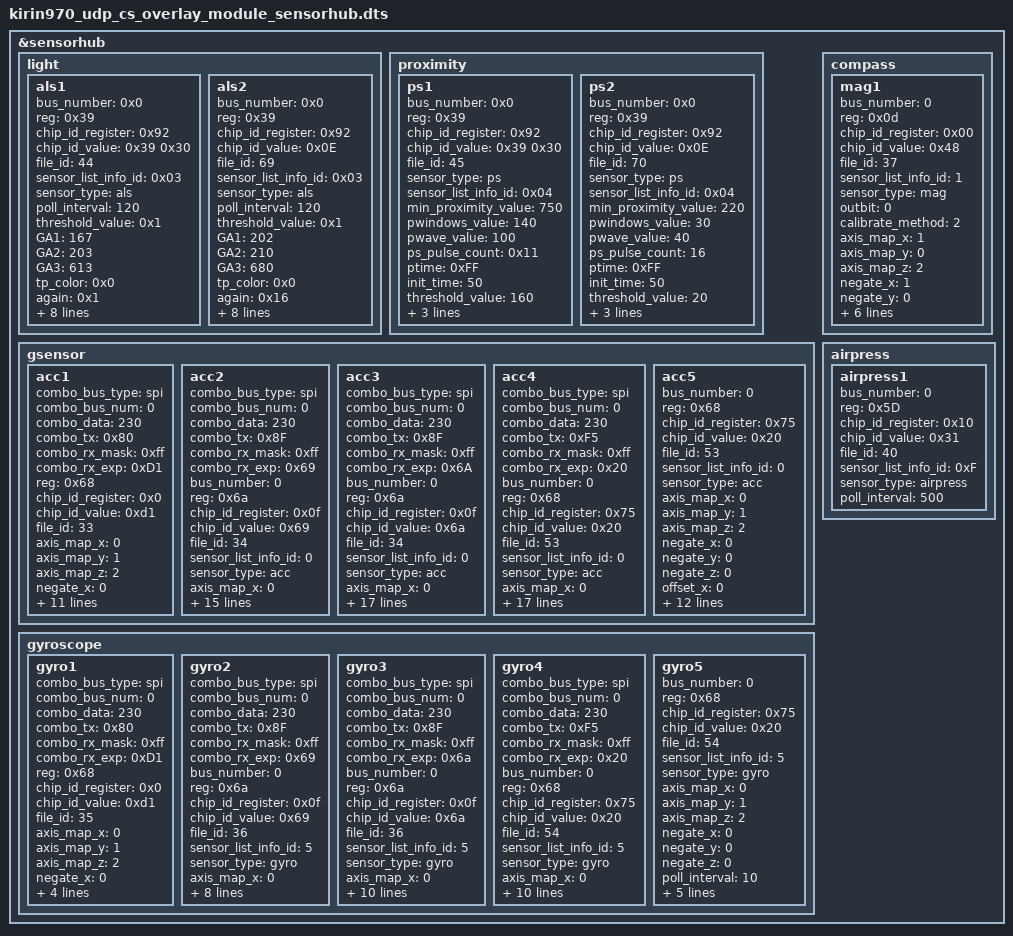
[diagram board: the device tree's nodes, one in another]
&sensorhub {
	#address-cells=<1>;
	#size-cells=<0>;
	light {
		als1 {
			bus_number = <0x0>;
			reg=<0x39>;
			chip_id_register = <0x92>;
			chip_id_value = <0x39 0x30>;
			file_id = <44>;
			sensor_list_info_id = <0x03>;
			sensor_type = "als";
			poll_interval = <120>;
			threshold_value = <0x1>;
			GA1 = <167>;
			GA2 = <203>;
			GA3 = <613>;
			tp_color = <0x0>;
			again = <0x1>;
			atime = <0xdb>;
			init_time = <0x96>;
			status = "ok";
			als_phone_type = <11>;
			als_phone_version = <11>;
			als_extend_data = <214 41 0x0 0x0 0x0 0x0 0x0 0x0 0x0 0x0 0x0 0x0>;
			sensorlist_name="light-apds993x";
			vendor="avago";
		};
		als2 {
			bus_number = <0x0>;
			reg=<0x39>;
			chip_id_register = <0x92>;
			chip_id_value = <0x0E>;
			file_id = <69>;
			sensor_list_info_id = <0x03>;
			sensor_type = "als";
			poll_interval = <120>;
			threshold_value = <0x1>;
			GA1 = <202>;
			GA2 = <210>;
			GA3 = <680>;
			tp_color = <0x0>;
			again = <0x16>;
			atime = <0x64>;
			init_time = <0x96>;
			status = "ok";
			als_phone_type = <11>;
			als_phone_version = <11>;
			als_extend_data = <4 0x0 0x0 0x0 0x0 0x0 0x0 0x0 0x0 0x0 0x0 0x0>;
			sensorlist_name="light-tmd2745";
			vendor="ams";
		};
	};

	proximity {
		ps1 {
			bus_number = <0x0>;
			reg = <0x39>;
			chip_id_register = <0x92>;
			chip_id_value = <0x39 0x30>;
			file_id = <45>;
			sensor_type = "ps";
			sensor_list_info_id = <0x04>;
			min_proximity_value = <750>;
			pwindows_value = <140>;
			pwave_value = <100>;
			ps_pulse_count=<0x11>;
			ptime=<0xFF>;
			init_time = <50>;
			status = "ok";
			threshold_value = <160>;
			/*gpio_int1 = <&gpio27 1 0>;*/
			poll_interval = <100>;
			sensorlist_name="proximity-apds993x";
			vendor="avago";
		};
		ps2 {
			bus_number = <0x0>;
			reg = <0x39>;
			chip_id_register = <0x92>;
			chip_id_value = <0x0E>;
			file_id = <70>;
			sensor_type = "ps";
			sensor_list_info_id = <0x04>;
			min_proximity_value = <220>;
			pwindows_value = <30>;
			pwave_value = <40>;
			ps_pulse_count=<16>;
			ptime=<0xFF>;
			init_time = <50>;
			status = "ok";
			threshold_value = <20>;
			/*gpio_int1 = <&gpio27 1 0>;*/
			poll_interval = <100>;
			sensorlist_name="proximity-tmd2745";
			vendor="ams";
		};
	};
	gsensor {
		acc1 {
			combo_bus_type = "spi";
			combo_bus_num = <0>;
			combo_data = <230>;
			combo_tx = /bits/ 8 <0x80>;
			combo_rx_mask = /bits/ 8 <0xff>;
			combo_rx_exp = /bits/ 8 <0xD1>;
			reg=<0x68>;
			chip_id_register=<0x0>;
			chip_id_value=<0xd1>;
			file_id=<33>;
			axis_map_x =<0>;
			axis_map_y =<1>;
			axis_map_z =<2>;
			negate_x =<0>;
			negate_y =<0>;
			negate_z =<0>;
			offset_x=<0>;
			offset_y=<0>;
			offset_z=<0>;
			sensitivity_x=<1>;
			sensitivity_y=<1>;
			sensitivity_z=<1>;
			gpio_int2=<&gpio25 7 0>;
			gpio_int2_sh=<1010>;
			calibrate_style=<0>;
			status = "ok";
		};
		acc2 {
			combo_bus_type = "spi";
			combo_bus_num = <0>;
			combo_data = <230>;
			combo_tx = /bits/ 8 <0x8F>;
			combo_rx_mask = /bits/ 8 <0xff>;
			combo_rx_exp = /bits/ 8 <0x69>;
			bus_number=<0>;
			reg=<0x6a>;
			chip_id_register=<0x0f>;
			chip_id_value=<0x69>;
			file_id=<34>;
			sensor_list_info_id=<0>;
			sensor_type="acc";
			/*sensor-vdd-supply = <&ldo24>;*/
			axis_map_x =<0>;
			axis_map_y =<1>;
			axis_map_z =<2>;
			negate_x =<0>;
			negate_y =<0>;
			negate_z =<0>;
			offset_x=<0>;
			offset_y=<0>;
			offset_z=<0>;
			sensitivity_x=<1>;
			sensitivity_y=<1>;
			sensitivity_z=<1>;
			poll_interval=<10>;
			gpio_int2=<&gpio25 7 0>;
			gpio_int2_sh=<1010>;
			calibrate_style=<0>;
			status = "ok";
		};
		acc3 {
			combo_bus_type = "spi";
			combo_bus_num = <0>;
			combo_data = <230>;
			combo_tx = /bits/ 8 <0x8F>;
			combo_rx_mask = /bits/ 8 <0xff>;
			combo_rx_exp = /bits/ 8 <0x6A>;
			bus_number =<0>;
			reg =<0x6a>;
			chip_id_register =<0x0f>;
			chip_id_value =<0x6a>;
			file_id =<34>;
			sensor_list_info_id =<0>;
			sensor_type ="acc";
			axis_map_x =<0>;
			axis_map_y =<1>;
			axis_map_z =<2>;
			negate_x =<0>;
			negate_y =<0>;
			negate_z =<0>;
			offset_x =<0>;
			offset_y =<0>;
			offset_z =<0>;
			sensitivity_x =<1>;
			sensitivity_y =<1>;
			sensitivity_z =<1>;
			poll_interval =<10>;
			gpio_int2=<&gpio25 7 0>;
			gpio_int2_sh=<1010>;
			calibrate_style=<0>;
			sensorlist_name="accelerometer-lsm6dsm";
			vendor="st";
			status = "ok";
		};
		acc4 {
			combo_bus_type = "spi";
			combo_bus_num = <0>;
			combo_data = <230>;
			combo_tx = /bits/ 8 <0xF5>;
			combo_rx_mask = /bits/ 8 <0xff>;
			combo_rx_exp = /bits/ 8 <0x20>;
			bus_number =<0>;
			reg =<0x68>;
			chip_id_register =<0x75>;
			chip_id_value =<0x20>;
			file_id =<53>;
			sensor_list_info_id =<0>;
			sensor_type ="acc";
			axis_map_x =<0>;
			axis_map_y =<1>;
			axis_map_z =<2>;
			negate_x =<0>;
			negate_y =<0>;
			negate_z =<0>;
			offset_x =<0>;
			offset_y =<0>;
			offset_z =<0>;
			sensitivity_x =<1>;
			sensitivity_y =<1>;
			sensitivity_z =<1>;
			poll_interval =<10>;
			gpio_int2=<&gpio25 7 0>;
			gpio_int2_sh=<1010>;
			calibrate_style =<0>;
			sensorlist_name="accelerometer-icm20690";
			vendor="invensense";
			status = "ok";
		};
		acc5 {
			bus_number =<0>;
			reg =<0x68>;
			chip_id_register =<0x75>;
			chip_id_value =<0x20>;
			file_id =<53>;
			sensor_list_info_id =<0>;
			sensor_type ="acc";
			axis_map_x =<0>;
			axis_map_y =<1>;
			axis_map_z =<2>;
			negate_x =<0>;
			negate_y =<0>;
			negate_z =<0>;
			offset_x =<0>;
			offset_y =<0>;
			offset_z =<0>;
			sensitivity_x =<1>;
			sensitivity_y =<1>;
			sensitivity_z =<1>;
			poll_interval =<10>;
			gpio_int1 =<&gpio26 0 0>;
			gpio_int2=<&gpio24 1 0>;
			gpio_int2_sh=<227>;
			calibrate_style =<0>;
			sensorlist_name="accelerometer-icm20690";
			vendor="invensense";
			status = "ok";
		};
	};

	gyroscope {
		gyro1 {
			combo_bus_type = "spi";
			combo_bus_num = <0>;
			combo_data = <230>;
			combo_tx = /bits/ 8 <0x80>;
			combo_rx_mask = /bits/ 8 <0xff>;
			combo_rx_exp = /bits/ 8 <0xD1>;
			reg=<0x68>;
			chip_id_register=<0x0>;
			chip_id_value=<0xd1>;
			file_id=<35>;
			axis_map_x =<0>;
			axis_map_y =<1>;
			axis_map_z =<2>;
			negate_x =<0>;
			negate_y =<0>;
			negate_z =<0>;
			gpio_int2=<&gpio25 7 0>;
			gpio_int2_sh=<1010>;
			status = "ok";
		};
		gyro2 {
			combo_bus_type = "spi";
			combo_bus_num = <0>;
			combo_data = <230>;
			combo_tx = /bits/ 8 <0x8F>;
			combo_rx_mask = /bits/ 8 <0xff>;
			combo_rx_exp = /bits/ 8 <0x69>;
			bus_number=<0>;
			reg=<0x6a>;
			chip_id_register=<0x0f>;
			chip_id_value=<0x69>;
			file_id=<36>;
			sensor_list_info_id=<5>;
			sensor_type="gyro";
			/*sensor-vdd-supply = <&ldo24>;*/
			axis_map_x =<0>;
			axis_map_y =<1>;
			axis_map_z =<2>;
			negate_x =<0>;
			negate_y =<0>;
			negate_z =<0>;
			poll_interval=<10>;
			gpio_int2=<&gpio25 7 0>;
			gpio_int2_sh=<1010>;
			status = "ok";
		};
		gyro3 {
			combo_bus_type = "spi";
			combo_bus_num = <0>;
			combo_data = <230>;
			combo_tx = /bits/ 8 <0x8F>;
			combo_rx_mask = /bits/ 8 <0xff>;
			combo_rx_exp = /bits/ 8 <0x6a>;
			bus_number =<0>;
			reg =<0x6a>;
			chip_id_register =<0x0f>;
			chip_id_value =<0x6a>;
			file_id =<36>;
			sensor_list_info_id =<5>;
			sensor_type ="gyro";
			axis_map_x =<0>;
			axis_map_y =<1>;
			axis_map_z =<2>;
			negate_x =<0>;
			negate_y =<0>;
			negate_z =<0>;
			poll_interval =<10>;
			gpio_int2=<&gpio25 7 0>;
			gpio_int2_sh=<1010>;
			sensorlist_name="gyroscope-lsm6dsm";
			vendor="st";
			status = "ok";
		};
		gyro4 {
			combo_bus_type = "spi";
			combo_bus_num = <0>;
			combo_data = <230>;
			combo_tx = /bits/ 8 <0xF5>;
			combo_rx_mask = /bits/ 8 <0xff>;
			combo_rx_exp = /bits/ 8 <0x20>;
			bus_number =<0>;
			reg =<0x68>;
			chip_id_register =<0x75>;
			chip_id_value =<0x20>;
			file_id =<54>;
			sensor_list_info_id =<5>;
			sensor_type ="gyro";
			axis_map_x =<0>;
			axis_map_y =<1>;
			axis_map_z =<2>;
			negate_x =<0>;
			negate_y =<0>;
			negate_z =<0>;
			poll_interval =<10>;
			gpio_int2=<&gpio25 7 0>;
			gpio_int2_sh=<1010>;
			sensorlist_name="gyroscope-icm20690";
			vendor="invensense";
			status = "ok";
		};
		gyro5 {
			bus_number =<0>;
			reg =<0x68>;
			chip_id_register =<0x75>;
			chip_id_value =<0x20>;
			file_id =<54>;
			sensor_list_info_id =<5>;
			sensor_type ="gyro";
			axis_map_x =<0>;
			axis_map_y =<1>;
			axis_map_z =<2>;
			negate_x =<0>;
			negate_y =<0>;
			negate_z =<0>;
			poll_interval =<10>;
			gpio_int1 =<&gpio26 2 0>;
			gpio_int2=<&gpio24 1 0>;
			gpio_int2_sh=<227>;
			sensorlist_name="gyroscope-icm20690";
			vendor="invensense";
			status = "ok";
		};
	};
	compass {
		mag1 {
			bus_number=<0>;
			reg=<0x0d>;
			chip_id_register=<0x00>;
			chip_id_value=<0x48>;
			file_id=<37>;
			sensor_list_info_id=<1>;
			sensor_type="mag";
			/*sensor-vdd-supply = <&ldo24>;*/
			outbit=<0>;
			calibrate_method=<2>;
			axis_map_x=<1>;
			axis_map_y=<0>;
			axis_map_z=<2>;
			negate_x=<1>;
			negate_y=<0>;
			negate_z=<0>;
			poll_interval=<10>;
			gpio_int1=<&gpio0 0 0>;
			gpio_reset=<&gpio0 0 0>;
			softiron_parameter = <13 39 19 255 59 00 19 255 59 41 221 255 59 00 221 255 102 42 0 0 0 0 0 0 0 0 0>;
			status = "ok";
		};
	};
	airpress {
		airpress1 {
			bus_number=<0>;
			reg=<0x5D>;
			chip_id_register=<0x10>;
			chip_id_value=<0x31>;
			file_id=<40>;
			sensor_list_info_id=<0xF>;
			sensor_type="airpress";
			poll_interval = <500>;
			status = "ok";
		};
	};
};
